# T113-S3 register map
Vendor: Allwinner; Series: T113-S3; File version: 0.1
CPU: other 0, little endian, MPU, no FPU, 0 interrupt priority bits
Registers are 32-bit, read-write, reset 0x0 unless marked. A register's access mark holds for its fields unless they carry their own. Offsets are from the block's base; [hi:lo] are bit positions; {n}, {i} and the like mark numbered series; 'fields as' and 'values as' point back to an identical list; <NAME> marks a mode.

## I2S/PCM1
Base 0x02033000
Same registers: I2S/PCM2 0x02034000
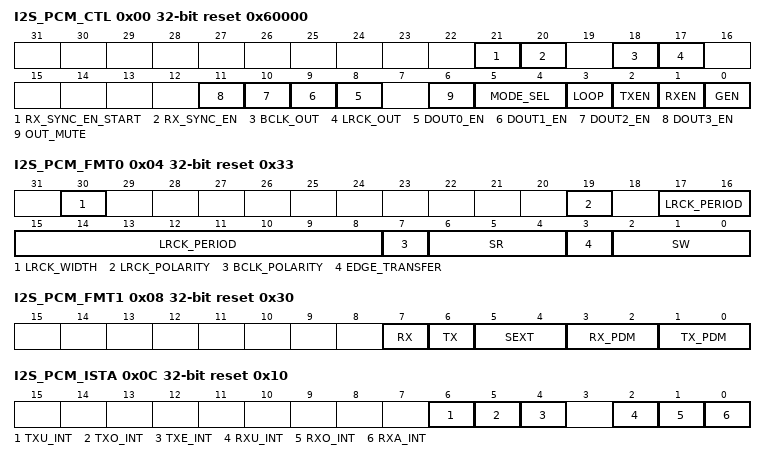
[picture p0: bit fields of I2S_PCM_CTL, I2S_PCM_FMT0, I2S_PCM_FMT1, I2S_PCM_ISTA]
0x00 I2S_PCM_CTL reset 0x60000
  [21] RX_SYNC_EN_START — The bit takes effect only when RX_SYNC_EN is set to 1. I2S1/I2S2/OWA RX Synchronize Enable Start. 0: Disabled 1: Enabled
    0=Disabled; 1=Enabled
  [20] RX_SYNC_EN — I2S RX Synchronize Enable 0: Disabled 1: Enabled
    0=Disabled; 1=Enabled
  [18] BCLK_OUT — Bit Clock Direction Select 0: Input 1: Output
    0=Input; 1=Output
  [17] LRCK_OUT — LRCK Direction Select 0: Input 1: Output
    0=Input; 1=Output
  [n+8] DOUT{n}_EN (n=0..3) — Data{n} Output Enable 0: Disabled, Hi-Z State 1: Enabled
    0=Disabled, Hi-Z State; 1=Enabled
  [6] OUT_MUTE — Data Output Mute Enable 0: Normal Transfer 1: Force DOUT to output 0
    0=Normal Transfer; 1=Force DOUT to output 0
  [5:4] MODE_SEL — Mode Selection 00: PCM Mode (offset 0: Long Frame; offset 1: Short Frame) 01: Left Mode (offset 0: LJ Mode; offset 1: I2S Mode) 10: Right-Justified Mode 11: Reserved
    0=PCM (PCM Mode (offset 0: Long Frame; offset 1: Short Frame)); 1=Left Mode (offset 0: LJ Mode; offset 1: I2S Mode); 2=Right-Justified Mode
  [3] LOOP — Loopback Test 0: Normal Mode 1: Loopback Test When set to `1`, the bit indicates that the DOUT is connected to the DIN.
    0=Normal Mode; 1=Loopback Test When set to `1`, the bit indicates that the DOUT is connected to the DIN
  [2] TXEN — Transmitter Block Enable 0: Disabled 1: Enabled
    0=Disabled; 1=Enabled
  [1] RXEN — Receiver Block Enable 0: Disabled 1: Enabled
    0=Disabled; 1=Enabled
  [0] GEN — Globe Enable 0: Disabled 1: Enabled
    0=Disabled; 1=Enabled
0x04 I2S_PCM_FMT0 reset 0x33
  [30] LRCK_WIDTH — LRCK Width (only applies to the PCM mode) 0: LRCK = 1 BCLK Width (Short Frame) 1: LRCK = 2 BCLK Width (Long Frame)
    0=LRCK__equals__1 (LRCK = 1 BCLK Width (Short Frame)); 1=LRCK__equals__2 (LRCK = 2 BCLK Width (Long Frame))
  [19] LRCK_POLARITY — In I2S/Left-Justified/Right-Justified mode: 0: Left Channel when LRCK is low. 1: Left channel when LRCK is high. In PCM mode: 0: PCM LRCK asserted at the negative edge. 1: PCM LRCK asserted at the positive edge.
    0=Left_Channel_when_LRCK_is_low; 1=Left channel when LRCK is high. In PCM mode:; 0=PCM LRCK asserted at the negative edge; 1=PCM LRCK asserted at the positive edge
  [17:8] LRCK_PERIOD — It is used to program the number of BCLKs per channel of the sample frame. This value is interpreted as follows. PCM mode: Number of BCLKs within (Left + Right) channel width. I2S/Left-Justified/Right-Justified mode: Number of BCLKs within each channel width (Left or Right). For example: N = 7: 8 BCLKs width ... N = 1023: 1024 BCLKs width
  [7] BCLK_POLARITY — 0: Normal mode, DOUT drives data at negative edge 1: Invert mode, DOUT drives data at positive edge
    0=Normal mode, DOUT drives data at negative edge; 1=Invert mode, DOUT drives data at positive edge
  [6:4] SR — Sample Resolution 000: Reserved 001: 8-bit 010: 12-bit 011: 16-bit 100: 20-bit 101: 24-bit 110: 28-bit 111: 32-bit
    1=_8_bit; 2=_12_bit; 3=_16_bit; 4=_20_bit; 5=_24_bit; 6=_28_bit; 7=_32_bit
  [3] EDGE_TRANSFER — Edge Transfer 0: DOUT drives data and DIN sample data at the different BCLK edge 1: DOUT drives data and DIN sample data at the same BCLK edge BCLK_POLARITY = 0, EDGE_TRANSFER = 0, DIN sample data at positive edge; BCLK_POLARITY = 0, EDGE_TRANSFER = 1, DIN sample data at negative edge; BCLK_POLARITY = 1, EDGE_TRANSFER = 0, DIN sample data at negative edge; BCLK_POLARITY = 1, EDGE_TRANSFER = 1, DIN sample data at positive edge.
    0=DOUT drives data and DIN sample data at the different BCLK edge; 1=DOUT drives data and DIN sample data at the same BCLK edge BCLK_POLARITY = 0, EDGE_TRANSFER = 0, DIN sample data at positive edge; BCLK_POLARITY = 0, EDGE_TRANSFER = 1, DIN sample data at negative edge; BCLK_POLARITY = 1, EDGE_TRANSFER = 0, DIN sample data at negative edge; BCLK_POLARITY = 1, EDGE_TRANSFER = 1, DIN sample data at positive edge
  [2:0] SW — Slot Width Select 000: Reserved 001: 8-bit 010: 12-bit 011: 16-bit 100: 20-bit 101: 24-bit 110: 28-bit 111: 32-bit
    values as SR
0x08 I2S_PCM_FMT1 reset 0x30
  [7] RX — MLS MSB/LSB First Select 0: MSB First 1: LSB First
    0=MSB (MSB First); 1=LSB (LSB First)
  [6] TX — MLS MSB/LSB First Select 0: MSB First 1: LSB First
    0=MSB (MSB First); 1=LSB (LSB First)
  [5:4] SEXT — Sign Extend in Slot [Sample Resolution < Slot Width] 00: Zeros or audio gain padding at LSB position 01: Sign extension at MSB position 10: Reserved 11: Transfer 0 after each sample in each Slot
    0=Zeros or audio gain padding at LSB position; 1=Sign extension at MSB position; 3=Transfer 0 after each sample in each Slot
  [3:2] RX_PDM — PCM Data Mode 00: Linear PCM 01: Reserved 10: 8-bit u-law 11: 8-bit A-law
    0=Linear_PCM; 2=_8_bit_ulaw; 3=_8_bit_Alaw
  [1:0] TX_PDM — PCM Data Mode 00: Linear PCM 01: Reserved 10: 8-bit u-law 11: 8-bit A-law
    0=Linear_PCM; 2=_8_bit_ulaw; 3=_8_bit_Alaw
0x0C I2S_PCM_ISTA reset 0x10
  [6] TXU_INT write-1-clears — TXFIFO Underrun Pending Interrupt 0: No pending interrupt 1: TXFIFO underrun pending interrupt Write `1` to clear this interrupt.
    0=No pending interrupt; 1=TXFIFO (TXFIFO underrun pending interrupt Write `1` to clear this interrupt.)
  [5] TXO_INT write-1-clears — TXFIFO Overrun Pending Interrupt 0: No pending interrupt 1: TXFIFO overrun pending interrupt Write `1` to clear this interrupt.
    0=No pending interrupt; 1=TXFIFO (TXFIFO overrun pending interrupt Write `1` to clear this interrupt.)
  [4] TXE_INT ro — TXFIFO Empty Pending Interrupt 0: No pending IRQ 1: TXFIFO empty pending interrupt when data in TXFIFO are less than TX trigger level
    0=No pending IRQ; 1=TXFIFO empty pending interrupt when data in TXFIFO are less than TX trigger level
  [2] RXU_INT write-1-clears — RXFIFO Underrun Pending Interrupt 0: No pending interrupt 1: RXFIFO underrun pending interrupt Write `1` to clear this interrupt.
    0=No pending interrupt; 1=RXFIFO (RXFIFO underrun pending interrupt Write `1` to clear this interrupt.)
  [1] RXO_INT write-1-clears — RXFIFO Overrun Pending Interrupt 0: No pending IRQ 1: RXFIFO overrun pending IRQ Write `1` to clear this interrupt.
    0=No pending IRQ; 1=RXFIFO (RXFIFO overrun pending IRQ Write `1` to clear this interrupt.)
  [0] RXA_INT — RXFIFO Data Available Pending Interrupt 0: No pending IRQ 1: Data available pending IRQ when data in RXFIFO are more than RX trigger level
    0=No pending IRQ; 1=Data available pending IRQ when data in RXFIFO are more than RX trigger level
0x10 I2S_PCM_RXFIFO
  [31:0] RX_DATA ro — RX Sample The host can get one sample by reading this register. The left channel sample data is first and then the right channel sample.
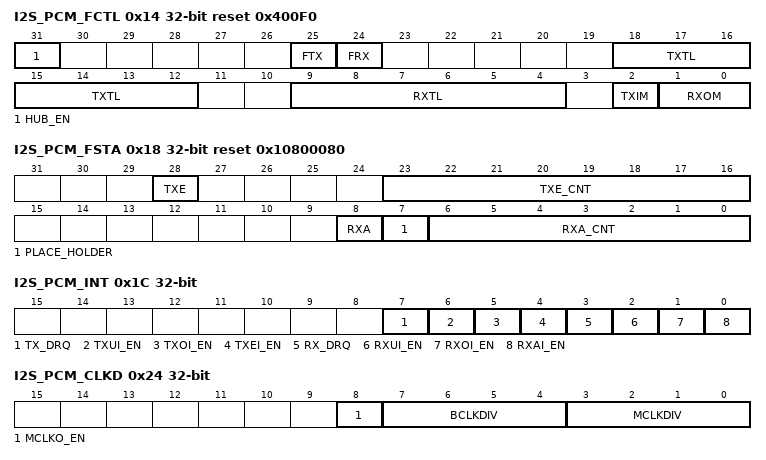
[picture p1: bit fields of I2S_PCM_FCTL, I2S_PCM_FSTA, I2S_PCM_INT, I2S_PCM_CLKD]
0x14 I2S_PCM_FCTL reset 0x400F0
  [31] HUB_EN — Audio Hub Enable The bit takes effect only when TXEN is set to 1. I2S1/I2S2/OWA TXFIFO Hub Enable. 0: Disabled 1: Enabled
    0=Disabled; 1=Enabled
  [25] FTX — Write `1` to flush TXFIFO, self clear to `0`.
  [24] FRX — Write `1` to flush RXFIFO, self clear to `0`.
  [18:12] TXTL — TXFIFO Empty Trigger Level Interrupt and DMA request trigger level for TXFIFO normal condition. Trigger Level = TXTL
  [9:4] RXTL — RXFIFO Trigger Level Interrupt and DMA request trigger level for RXFIFO normal condition. Trigger Level = RXTL + 1
  [2] TXIM — TXFIFO Input Mode (Mode 0, 1) 0: Valid data at the MSB of TXFIFO register 1: Valid data at the LSB of TXFIFO register Example for 20-bit transmitted audio sample: Mode 0: TXFIFO[31:0] = {APB_WDATA[31:12], 12`h0} Mode 1: TXFIFO[31:0] = {APB_WDATA[19:0], 12`h0}
    0=Valid data at the MSB of TXFIFO register; 1=Valid data at the LSB of TXFIFO register Example for 20-bit transmitted audio sample: Mode 0: TXFIFO[31:0] = {APB_WDATA[31:12], 12`h0} Mode 1: TXFIFO[31:0] = {APB_WDATA[19:0], 12`h0}
  [1:0] RXOM — RXFIFO Output Mode (Mode 0, 1, 2, 3) 00: Expanding `0` at LSB of RXFIFO register 01: Expanding received sample sign bit at MSB of RXFIFO register 10: Truncating received samples at high half-word of RXFIFO register and low half-word of RXFIFO register is filled by `0` 11: Truncating received samples at low half-word of RXFIFO register and high half-word of RXFIFO register is expanded by its sign bit Example for 20-bit received audio sample: Mode 0: APB_RDATA[31:0] = {RXFIFO[31:12], 12`h0} Mode 1: APB_RDATA[31:0] = {12{RXFIFO[31]}, RXFIFO[31:12]} Mode 2: APB_RDATA [31:0] = {RXFIFO[31:16], 16`h0} Mode 3: APB_RDATA[31:0] = {16{RXFIFO[31], RXFIFO[31:16]}
    0=Expanding `0` at LSB of RXFIFO register; 1=Expanding received sample sign bit at MSB of RXFIFO register; 2=Truncating received samples at high half-word of RXFIFO register and low half-word of RXFIFO register is filled by `0`; 3=Truncating received samples at low half-word of RXFIFO register and high half-word of RXFIFO register is expanded by its sign bit Example for 20-bit received audio sample: Mode 0: APB_RDATA[31:0] = {RXFIFO[31:12], 12`h0} Mode 1: APB_RDATA[31:0] = {12{RXFIFO[31]}, RXFIFO[31:12]} Mode 2: APB_RDATA [31:0] = {RXFIFO[31:16], 16`h0} Mode 3: APB_RDATA[31:0] = {16{RXFIFO[31], RXFIFO[31:16]}
0x18 I2S_PCM_FSTA reset 0x10800080
  [28] TXE ro — TXFIFO Empty 0: No room for new sample in TXFIFO 1: More than one room for new sample in TXFIFO (>= 1 Word)
    0=No room for new sample in TXFIFO; 1=More than one room for new sample in TXFIFO (>= 1 Word)
  [23:16] TXE_CNT ro — TXFIFO Empty Space Word Counter
  [8] RXA ro — RXFIFO Available 0: No available data in RXFIFO 1: More than one sample in RXFIFO (>= 1 Word)
    0=No available data in RXFIFO; 1=More than one sample in RXFIFO (>= 1 Word)
  [7] PLACE_HOLDER ro — NO Meaning.
  [6:0] RXA_CNT ro — RXFIFO available sample word counter
0x1C I2S_PCM_INT
  [7] TX_DRQ — TXFIFO Empty DRQ Enable 0: Disabled 1: Enabled
    0=Disabled; 1=Enabled
  [6] TXUI_EN — TXFIFO Underrun Interrupt Enable 0: Disabled 1: Enabled
    0=Disabled; 1=Enabled
  [5] TXOI_EN — TXFIFO Overrun Interrupt Enable 0: Disabled 1: Enabled When set to `1`, an interrupt happens when writing new audio data if TXFIFO is full.
    0=Disabled; 1=Enabled When set to `1`, an interrupt happens when writing new audio data if TXFIFO is full
  [4] TXEI_EN — TXFIFO Empty Interrupt Enable 0: Disabled 1: Enabled
    0=Disabled; 1=Enabled
  [3] RX_DRQ — RXFIFO Data Available DRQ Enable 0: Disabled 1: Enabled When set to `1`, RXFIFO DMA request line is asserted if data is available in RXFIFO.
    0=Disabled; 1=Enabled When set to `1`, RXFIFO DMA request line is asserted if data is available in RXFIFO
  [2] RXUI_EN — RXFIFO Underrun Interrupt Enable 0: Disabled 1: Enabled
    0=Disabled; 1=Enabled
  [1] RXOI_EN — RXFIFO Overrun Interrupt Enable 0: Disabled 1: Enabled
    0=Disabled; 1=Enabled
  [0] RXAI_EN — RXFIFO Data Available Interrupt Enable 0: Disabled 1: Enabled
    0=Disabled; 1=Enabled
0x20 I2S_PCM_TXFIFO
  [31:0] TX_DATA wo — TX Sample Transmitting left, right channel sample data should be written to this register one by one. The left channel sample data is first and then the right channel sample.
0x24 I2S_PCM_CLKD
  [8] MCLKO_EN — 0: Disable MCLK Output 1: Enable MCLK Output
    0=Disable MCLK Output; 1=Enable MCLK Output
  [7:4] BCLKDIV — BCLK Divide Ratio from PLL_AUDIO 0000: Reserved 0001: Divide by 1 0010: Divide by 2 0011: Divide by 4 0100: Divide by 6 0101: Divide by 8 0110: Divide by 12 0111: Divide by 16 1000: Divide by 24 1001: Divide by 32 1010: Divide by 48 1011: Divide by 64 1100: Divide by 96 1101: Divide by 128 1110: Divide by 176 1111: Divide by 192
    1=Divide_by_1; 2=Divide_by_2; 3=Divide_by_4; 4=Divide_by_6; 5=Divide_by_8; 6=Divide_by_12; 7=Divide_by_16; 8=Divide_by_24; 9=Divide_by_32; 10=Divide_by_48; 11=Divide_by_64; 12=Divide_by_96; 13=Divide_by_128; 14=Divide_by_176; 15=Divide_by_192
  [3:0] MCLKDIV — MCLK Divide Ratio from PLL_AUDIO 0000: Reserved 0001: Divide by 1 0010: Divide by 2 0011: Divide by 4 0100: Divide by 6 0101: Divide by 8 0110: Divide by 12 0111: Divide by 16 1000: Divide by 24 1001: Divide by 32 1010: Divide by 48 1011: Divide by 64 1100: Divide by 96 1101: Divide by 128 1110: Divide by 176 1111: Divide by 192
    values as BCLKDIV
0x28 I2S_PCM_TXCNT
  [31:0] TX_CNT — TX Sample Counter The audio sample number of sending into TXFIFO. When one sample is put into TXFIFO by DMA or by host IO, the TX sample counter register increases by one. The TX sample counter register can be set to any initial value at any time. After being updated by the initial value, the counter register should count on the base of this initial value.
0x2C I2S_PCM_RXCNT
  [31:0] RX_CNT — RX Sample Counter The audio sample number of writing into RXFIFO. When one sample is written by Digital Audio Engine, the RX sample counter register increases by one. The RX sample counter register can be set to any initial value at any time. After being updated by the initial value, the counter register should count on the base of this initial value.
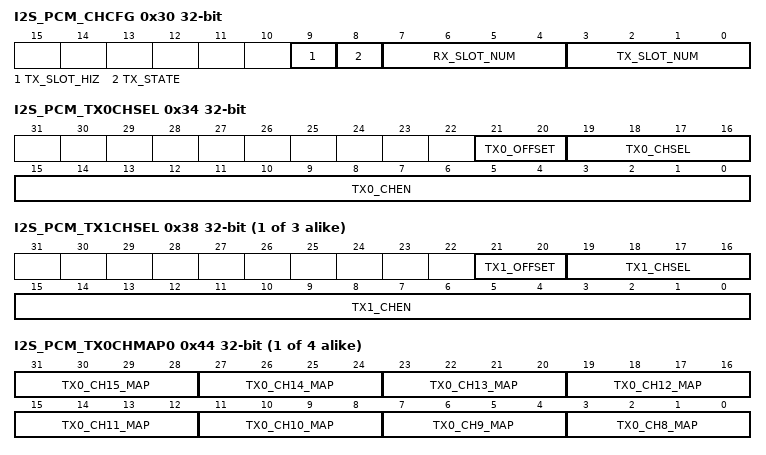
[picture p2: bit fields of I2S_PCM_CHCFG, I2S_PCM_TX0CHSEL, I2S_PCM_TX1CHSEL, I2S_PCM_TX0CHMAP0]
0x30 I2S_PCM_CHCFG
  [9] TX_SLOT_HIZ — 0: Normal mode for the last half-cycle of BCLK in the slot 1: Turn to Hi-Z state for the last half-cycle of BCLK in the slot
    0=Normal mode for the last half-cycle of BCLK in the slot; 1=Turn to Hi-Z state for the last half-cycle of BCLK in the slot
  [8] TX_STATE — 0: Transfer level 0 in non-transferring slot 1: Turn to Hi-Z State (TDM) in non-transferring slot
    0=Transfer level 0 in non-transferring slot; 1=Turn to Hi-Z State (TDM) in non-transferring slot
  [7:4] RX_SLOT_NUM — RX Channel/Slot number between CPU/DMA and RXFIFO 0000: 1 channel or slot ... 0111: 8 channels or slots 1000: 9 channels or slots ... 1111: 16 channels or slots
    0=1 channel or slot ; 7=8 channels or slots; 8=9 channels or slots ; 15=16 channels or slots
  [3:0] TX_SLOT_NUM — TX Channel/Slot number between CPU/DMA and TXFIFO 0000: 1 channel or slot ... 0111: 8 channels or slots 1000: 9 channels or slots ... 1111:16 channels or slots
    0=1 channel or slot ; 7=8 channels or slots; 8=9 channels or slots ... 1111:16 channels or slots
0x34 I2S_PCM_TX0CHSEL
  [21:20] TX0_OFFSET — TX0 Offset Tune (TX0 Data offset to LRCK) 0: No offset n: Data is offset by n BCLKs to LRCK
  [19:16] TX0_CHSEL — TX0 Channel (Slot) Number Select for Each Output 0000: 1 channel or slot ... 0111: 8 channels or slots 1000: 9 channels or slots ... 1111: 16 channels or slots
    values as I2S_PCM_CHCFG.RX_SLOT_NUM
  [15:0] TX0_CHEN — TX0 Channel (Slot) Enable The bit[15:0] refer to Slot [15:0]. When one or more slots are disabled, the affected slots are set to the disable state. 0: Disabled 1: Enabled
{0x34+4i} I2S_PCM_TX{i}CHSEL (i=1..3)
  [21:20] TX{i}_OFFSET — TX{i} Offset Tune (TX{i} Data offset to LRCK) 0: No offset n: Data is offset by n BCLKs to LRCK
  [19:16] TX{i}_CHSEL — TX{i} Channel (Slot) Number Select for Each Output 0000: 1 channel or slot ... 0111: 8 channels or slots 1000: 9 channels or slots ... 1111: 16 channels or slots
    values as I2S_PCM_CHCFG.RX_SLOT_NUM
  [15:0] TX{i}_CHEN — TX{i} Channel (Slot) Enable The bit[15:0] refers to Slot [15:0]. When one or more slots are disabled, the affected slots are set to the disable state. 0: Disabled 1: Enabled
{0x44+8i} I2S_PCM_TX{i}CHMAP0 (i=0..3)
  [all] fields
    0=first_sample (The first sample ...); 7=eighth_sample (The eighth sample); 8=ninth_sample (The ninth sample ...); 15=sixteenth_sample (The sixteenth sample)
  [4n-29:4n-32] TX{i}_CH{n}_MAP (n=8..15) — TX{i} Channel {n} Mapping 0000: The first sample ... 0111: The eighth sample 1000: The ninth sample ... 1111: The sixteenth sample
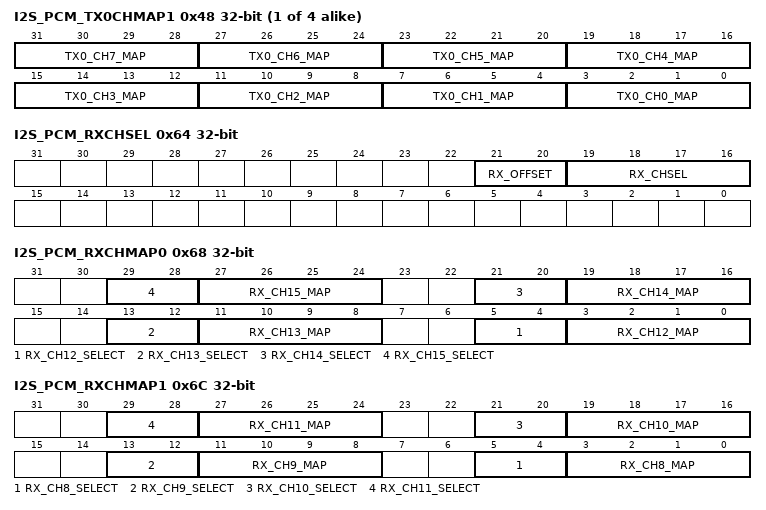
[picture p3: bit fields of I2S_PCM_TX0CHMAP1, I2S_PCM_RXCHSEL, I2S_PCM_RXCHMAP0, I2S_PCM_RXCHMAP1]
{0x48+8i} I2S_PCM_TX{i}CHMAP1 (i=0..3)
  [all] fields
    values as the fields of I2S_PCM_TX0CHMAP0
  [4n+3:4n] TX{i}_CH{n}_MAP (n=0..7) — TX{i} Channel {n} Mapping 0000: The first sample ... 0111: The eighth sample 1000: The ninth sample ... 1111: The sixteenth sample
0x64 I2S_PCM_RXCHSEL
  [21:20] RX_OFFSET — RX Offset Tune (RX Data offset to LRCK) 0: No offset n: Data is offset by n BCLKs to LRCK
  [19:16] RX_CHSEL — RX Channel (Slot) Number Select for Input 0000: 1 channel or slot ... 0111: 8 channels or slots 1000: 9 channels or slots ... 1111: 16 channels or slots
    values as I2S_PCM_CHCFG.RX_SLOT_NUM
0x68 I2S_PCM_RXCHMAP0
  [8n-91:8n-92] RX_CH{n}_SELECT (n=12..15) — RX Channel {n} Select 00: SDI0 01: SDI1 10: SDI2 11: SDI3
    {v}=SDI{v} (v=0..3)
  [8n-93:8n-96] RX_CH{n}_MAP (n=12..15) — RX Channel {n} Mapping 0000: The first sample ... 0111: The eighth sample 1000: The ninth sample ... 1111: The sixteenth sample
    values as the fields of I2S_PCM_TX0CHMAP0
0x6C I2S_PCM_RXCHMAP1
  [8n-59:8n-60] RX_CH{n}_SELECT (n=8..11) — RX Channel {n} Select 00: SDI0 01: SDI1 10: SDI2 11: SDI3
    {v}=SDI{v} (v=0..3)
  [8n-61:8n-64] RX_CH{n}_MAP (n=8..11) — RX Channel {n} Mapping 0000: The first sample ... 0111: The eighth sample 1000: The ninth sample ... 1111: The sixteenth sample
    values as the fields of I2S_PCM_TX0CHMAP0
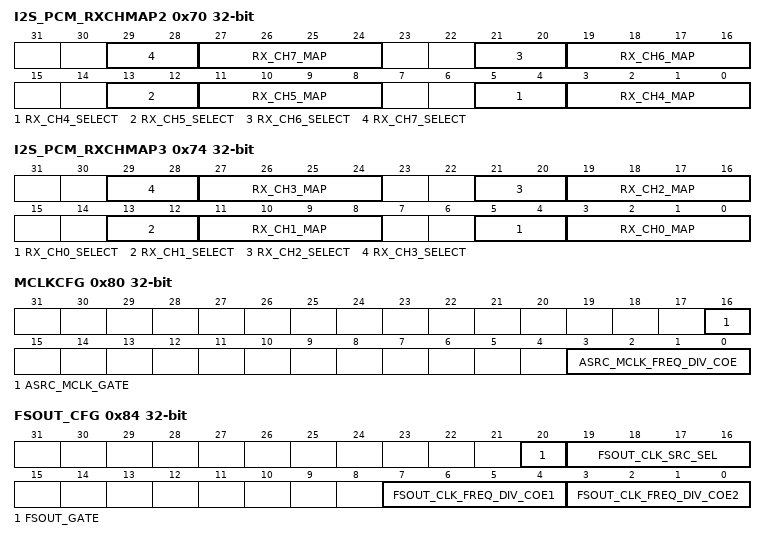
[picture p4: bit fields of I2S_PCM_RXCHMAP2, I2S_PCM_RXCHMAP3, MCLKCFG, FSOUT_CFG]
0x70 I2S_PCM_RXCHMAP2
  [8n-27:8n-28] RX_CH{n}_SELECT (n=4..7) — RX Channel {n} Select 00: SDI0 01: SDI1 10: SDI2 11: SDI3
    {v}=SDI{v} (v=0..3)
  [8n-29:8n-32] RX_CH{n}_MAP (n=4..7) — RX Channel {n} Mapping 0000: The first sample ... 0111: The eighth sample 1000: The ninth sample ... 1111: The sixteenth sample
    values as the fields of I2S_PCM_TX0CHMAP0
0x74 I2S_PCM_RXCHMAP3
  [8n+5:8n+4] RX_CH{n}_SELECT (n=0..3) — RX Channel {n} Select 00: SDI0 01: SDI1 10: SDI2 11: SDI3
    {v}=SDI{v} (v=0..3)
  [8n+3:8n] RX_CH{n}_MAP (n=0..3) — RX Channel {n} Mapping 0000: The first sample ... 0111: The eighth sample 1000: The ninth sample ... 1111: The sixteenth sample
    values as the fields of I2S_PCM_TX0CHMAP0
0x80 MCLKCFG — ASRC MCLK Configuration Register
  [16] ASRC_MCLK_GATE — ASRC Clock Gate Enable Control 0: Gated 1: Not gated
    0=Gated; 1=Not_gated
  [3:0] ASRC_MCLK_FREQ_DIV_COE — Frequency Division Coefficient 4`d0 = Res (no output), 4`d1 = 1x, 4`d2 = 1/2x, 4`d3 = 1/4x, 4`d4 = 1/6x, 4`d5 = 1/8x, 4`d6 = 1/12x, 4`d7 = 1/16x, 4`d8 = 1/24x, 4`d9 = 1/32x, 4`d10 = 1/48, 4`d11 = 1/64x, 4`d12 = 1/96x, 4`d13 = 1/128x, 4`d14 = 1/176x, 4`d15 = 1/192x, others = Res
0x84 FSOUT_CFG
  [20] FSOUT_GATE — fsout Clock Gate Enable Control 0: Gated 1: Not gated
    0=Gated; 1=Not_gated
  [19:16] FSOUT_CLK_SRC_SEL — fsout Clock Source Select 00: I2S0_ASRC_CLK 01: ACLK 10: ACLKM 11: BCLK Others: Reserved
  [7:4] FSOUT_CLK_FREQ_DIV_COE1 — fsout Frequency Division Coefficient 1 The First Division Factor It has two levels of frequency division, the first level is bit[7:4], the second level is bit[3:0], and the frequency division factors are multiplied by the two division factors, the division relationship of the two divisions are the same. 4`d0 = Res (no output), 4`d1 = 1x, 4`d2 = 1/2x, 4`d3 = 1/4x, 4`d4 = 1/6x, 4`d5 = 1/8x, 4`d6 = 1/12x, 4`d7 = 1/16x, 4`d8 = 1/24x, 4`d9 = 1/32x, 4`d10 = 1/48, 4`d11 = 1/64x, 4`d12 = 1/96x, 4`d13 = 1/128x, 4`d14 = 1/176x, 4`d15 = 1/192x
  [3:0] FSOUT_CLK_FREQ_DIV_COE2 — fsout Frequency Division Coefficient 2 The Second Division Factor 4`d0 = Res (no output), 4`d1 = 1x, 4`d2 = 1/2x, 4`d3 = 1/4x, 4`d4 = 1/6x, 4`d5 = 1/8x, 4`d6 = 1/12x, 4`d7 = 1/16x, 4`d8 = 1/24x, 4`d9 = 1/32x, 4`d10 = 1/48, 4`d11 = 1/64x, 4`d12 = 1/96x, 4`d13 = 1/128x, 4`d14 = 1/176x, 4`d15 = 1/192x
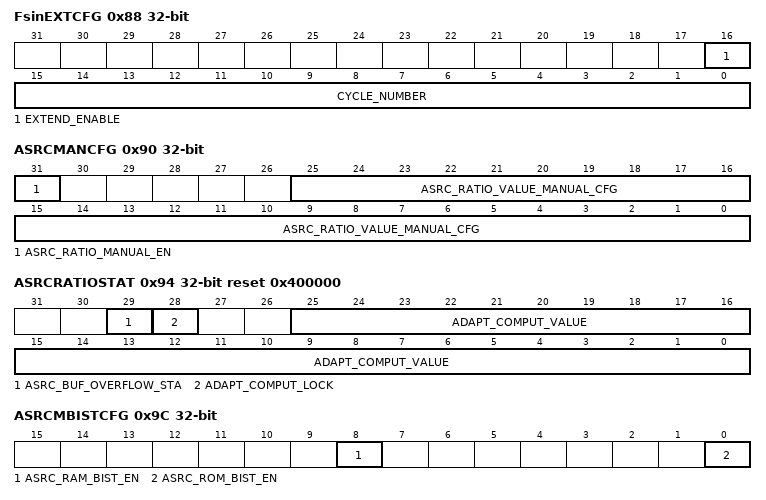
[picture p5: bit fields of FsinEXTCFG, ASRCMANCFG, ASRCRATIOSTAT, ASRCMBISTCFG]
0x88 FsinEXTCFG — ASRC Input Sample Pulse Extend Configuration Register
  [16] EXTEND_ENABLE — Extend Enable 0: Disabled 1: Enabled Enable the bit when using ASRC.
    0=Disabled; 1=Enabled Enable the bit when using ASRC
  [15:0] CYCLE_NUMBER — The Cycle Number of Pulse Extend The cycle is BCLK clock and is 1 at least.
0x8C ASRCEN
  [0] ASRC — Function Enable 0: Disabled 1: Enabled
    0=Disabled; 1=Enabled
0x90 ASRCMANCFG — ASRC Manual Ratio Configuration Register
  [31] ASRC_RATIO_MANUAL_EN — Manual Configuration of ASRC Ratio Enable 0: Disabled 1: Enabled
    0=Disabled; 1=Enabled
  [25:0] ASRC_RATIO_VALUE_MANUAL_CFG — ASRC Ratio Value Manual Configure The ratio value is an unsigned 26-bit number and uses 4.22 data format, which means there are 4 bits to the left of the decimal point and 22 bits to the right of the decimal point.
0x94 ASRCRATIOSTAT reset 0x400000 — ASRC Status Register
  [29] ASRC_BUF_OVERFLOW_STA ro — ASRC Receive Data Buffer Overflow State It can control the mute with lock. 0: No overflow 1: Overflow
    0=No_overflow; 1=Overflow
  [28] ADAPT_COMPUT_LOCK ro — Adaptive Ratio Computational Lock 0: Unlocked 1: Locked
    0=Unlocked; 1=Locked
  [25:0] ADAPT_COMPUT_VALUE ro — Adaptive Ratio Computational Value
0x98 ASRCFIFOSTAT — ASRC FIFO Level Status Register
  [8:0] ASRC_RX_FIFO_FULL_LEVAL ro — ASRC RXFIFO Full Level The manually-configured FIFO fill level for the ratio value of the received data.
0x9C ASRCMBISTCFG — ASRC MBIST Test Configuration Register
  [8] ASRC_RAM_BIST_EN — ASRC RAM BIST Enable Enable the RAM BIST.
  [0] ASRC_ROM_BIST_EN — ASRC ROM BIST Enable Enable the ROM BIST.
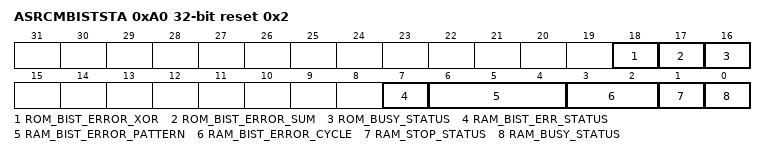
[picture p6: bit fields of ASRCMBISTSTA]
0xA0 ASRCMBISTSTA reset 0x2
  [18] ROM_BIST_ERROR_XOR ro
  [17] ROM_BIST_ERROR_SUM ro
  [16] ROM_BUSY_STATUS ro — ROM BUSY STATUS 1: ROM busy 0: ROM idle
    1=ROM (ROM busy); 0=ROM_idle
  [7] RAM_BIST_ERR_STATUS ro — RAM BIST error status 1: Error 0: No effect
    1=Error; 0=No_effect
  [6:4] RAM_BIST_ERROR_PATTERN ro
  [3:2] RAM_BIST_ERROR_CYCLE ro
  [1] RAM_STOP_STATUS ro — RAM stop status 1: Stop 0: Running
    1=Stop; 0=Running
  [0] RAM_BUSY_STATUS ro — RAM busy status 1: RAM busy 0: RAM idle
    1=RAM (RAM busy); 0=RAM_idle
